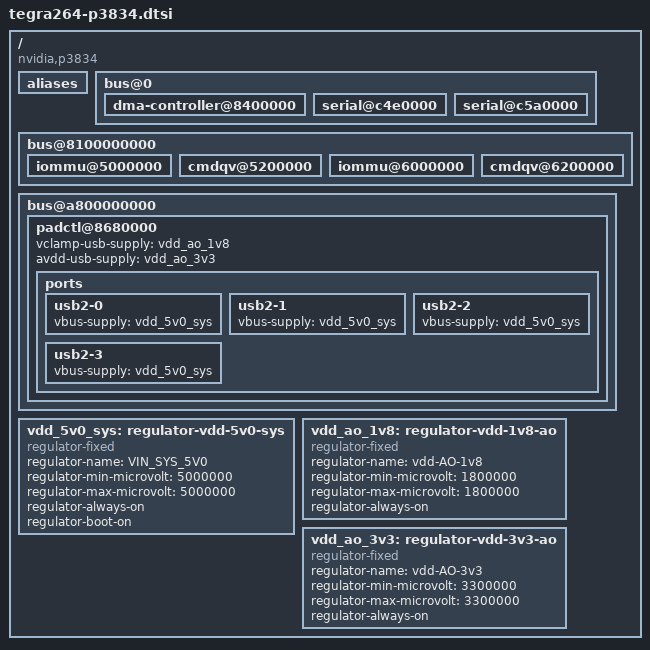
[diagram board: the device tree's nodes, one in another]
// SPDX-License-Identifier: GPL-2.0-only OR BSD-2-Clause

#include "tegra264.dtsi"

/ {
	compatible = "nvidia,p3834", "nvidia,tegra264";

	aliases {
	};

	bus@0 {
		dma-controller@8400000 {
			status = "okay";
		};

		serial@c4e0000 {
			status = "okay";
		};

		serial@c5a0000 {
			status = "okay";
		};
	};

	bus@8100000000 {
		iommu@5000000 {
			status = "okay";
		};

		cmdqv@5200000 {
			status = "okay";
		};

		iommu@6000000 {
			status = "okay";
		};

		cmdqv@6200000 {
			status = "okay";
		};
	};

	bus@a800000000 {
		padctl@8680000 {
			vclamp-usb-supply = <&vdd_ao_1v8>;
			avdd-usb-supply = <&vdd_ao_3v3>;

			ports {
				usb2-0 {
					vbus-supply = <&vdd_5v0_sys>;
				};

				usb2-1 {
					vbus-supply = <&vdd_5v0_sys>;
				};

				usb2-2 {
					vbus-supply = <&vdd_5v0_sys>;
				};

				usb2-3 {
					vbus-supply = <&vdd_5v0_sys>;
				};
			};
		};
	};

	vdd_5v0_sys: regulator-vdd-5v0-sys {
		compatible = "regulator-fixed";
		regulator-name = "VIN_SYS_5V0";
		regulator-min-microvolt = <5000000>;
		regulator-max-microvolt = <5000000>;
		regulator-always-on;
		regulator-boot-on;
	};

	vdd_ao_1v8: regulator-vdd-1v8-ao {
		compatible = "regulator-fixed";
		regulator-name = "vdd-AO-1v8";
		regulator-min-microvolt = <1800000>;
		regulator-max-microvolt = <1800000>;
		regulator-always-on;
	};

	vdd_ao_3v3: regulator-vdd-3v3-ao {
		compatible = "regulator-fixed";
		regulator-name = "vdd-AO-3v3";
		regulator-min-microvolt = <3300000>;
		regulator-max-microvolt = <3300000>;
		regulator-always-on;
	};
};
